# netx90_app register map
File version: 1.0
CPU: CM4 r0p1, little endian, MPU, FPU, 4 interrupt priority bits, 78 interrupts
Registers are 32-bit, read-write, reset 0x0 unless marked. A register's access mark holds for its fields unless they carry their own. Offsets are from the block's base; [hi:lo] are bit positions; 'fields as' and 'values as' point back to an identical list.

## aes
Base 0xFF080300
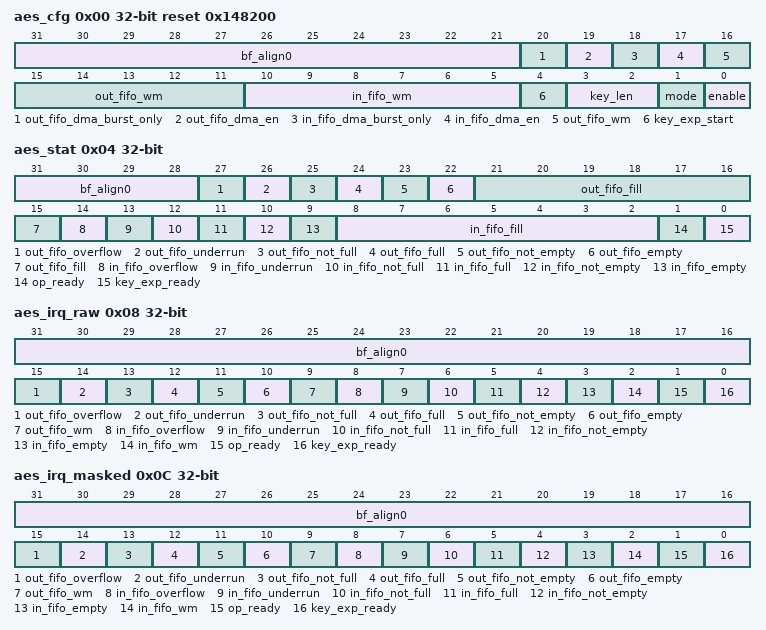
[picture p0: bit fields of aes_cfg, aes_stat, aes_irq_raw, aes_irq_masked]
0x00 aes_cfg reset 0x148200 (reset mask 0x1FFFFF) — AES config register
  [31:21] bf_align0 — bitField alignment value for aeabi compatibility
  [20] out_fifo_dma_burst_only — Generate DMAC burst signal only (output FIFO). When set to '1' the DMAC logic will only generate burst requests to the DMAC. This is not strictly needed for the DMAC implementation, but could result in better system performance.
  [19] out_fifo_dma_en — Enable DMAC control signals for the output FIFO.
  [18] in_fifo_dma_burst_only — Generate DMAC burst signal only (input FIFO). When set to '1' the DMAC logic will only generate burst requests to the DMAC. This is to overcome limitations of the current DMA controller implementation that only accepts burst requests for DMAC controlled memory to peripheral transfers.
  [17] in_fifo_dma_en — Enable DMAC control signals for the input FIFO
  [16:11] out_fifo_wm — Output FIFO watermark level (0..63) used for out_fifo_wm interrupt
  [10:5] in_fifo_wm — Input FIFO watermark level (0..63) used for in_fifo_wm interrupt
  [4] key_exp_start — Start AES key expansion After writing '1', this bit will automatically be reset. Data input can be started when key expansion is ready (see crypt_aes_stat bit 'key_exp_ready').
  [3:2] key_len — AES key length 0: 128 bit 1: 192 bit 2: 256 bit 3: reserved
  [1] mode — AES core operation mode 0: Encrypt 1: Decrypt
  [0] enable — Enables the AES core operation.
0x04 aes_stat ro (reset mask 0xFFFFFFF) — AES status register
  [31:28] bf_align0 — bitField alignment value for aeabi compatibility
  [27] out_fifo_overflow — Output FIFO was overflown, set aes_cfg-enable=0 to reset this bit Note: overflow is only a theoretical FIFO status, because the hardware logic of the AES core won't put data into the FIFO when it's full.
  [26] out_fifo_underrun — Output FIFO was underrun, set aes_cfg-enable=0 to reset this bit
  [25] out_fifo_not_full — Output FIFO is not full
  [24] out_fifo_full — Output FIFO is full
  [23] out_fifo_not_empty — Output FIFO is not empty
  [22] out_fifo_empty — Output FIFO is empty
  [21:15] out_fifo_fill — Fill level of output FIFO in bytes (0..64)
  [14] in_fifo_overflow — Input FIFO was overflown, set aes_cfg-enable=0 to reset this bit
  [13] in_fifo_underrun — Input FIFO was underrun, set aes_cfg-enable=0 to reset this bit Note: underrun is only a theoretical FIFO status, because the hardware logic of the AES core won't fetch data from the FIFO when it's empty.
  [12] in_fifo_not_full — Input FIFO is not full
  [11] in_fifo_full — Input FIFO is full
  [10] in_fifo_not_empty — Input FIFO is not empty
  [9] in_fifo_empty — Input FIFO is empty
  [8:2] in_fifo_fill — Fill level of input FIFO in bytes (0..64)
  [1] op_ready — Set when AES operation ready, i.e. AES core not busy and input FIFO is empty
  [0] key_exp_ready — Set when key expansion procedure is done
0x08 aes_irq_raw (reset mask 0xFFFF) — AES raw IRQ: Read access shows status of unmasked IRQs. IRQs are set automatically and reset by writing to this register: Write access with '1' resets the appropriate IRQ. Write access with '0' does not influence this bit.
  [31:16] bf_align0 — bitField alignment value for aeabi compatibility
  [15] out_fifo_overflow — Output FIFO was overflown, set aes_cfg-enable=0 to reset this bit Note: overflow is only a theoretical FIFO status, because the hardware logic of the AES core won't put data into the FIFO when it's full.
  [14] out_fifo_underrun — Output FIFO was underrun, set aes_cfg-enable=0 to reset this bit
  [13] out_fifo_not_full — Output FIFO is not full
  [12] out_fifo_full — Output FIFO is full
  [11] out_fifo_not_empty — Output FIFO is not empty
  [10] out_fifo_empty — Output FIFO is empty
  [9] out_fifo_wm — Fill level of output FIFO is above watermark (see crypt_aes_cfg bits 'out_fifo_wm')
  [8] in_fifo_overflow — Input FIFO was overflown, set aes_cfg-enable=0 to reset this bit
  [7] in_fifo_underrun — Input FIFO was underrun, set aes_cfg-enable=0 to reset this bit Note: underrun is only a theoretical FIFO status, because the hardware logic of the AES core won't fetch data from the FIFO when it's empty.
  [6] in_fifo_not_full — Input FIFO is not full
  [5] in_fifo_full — Input FIFO is full
  [4] in_fifo_not_empty — Input FIFO is not empty
  [3] in_fifo_empty — Input FIFO is empty
  [2] in_fifo_wm — Fill level of input FIFO is below or equal watermark (see crypt_aes_cfg bits 'in_fifo_wm')
  [1] op_ready — Set when AES operation ready, i.e. AES core not busy and input FIFO is empty
  [0] key_exp_ready — Set when key expansion procedure is done
0x0C aes_irq_masked ro (reset mask 0xFFFF) — AES masked IRQ: Shows status of masked IRQs.
  [31:16] bf_align0 — bitField alignment value for aeabi compatibility
  [15] out_fifo_overflow — Output FIFO was overflown, set aes_cfg-enable=0 to reset this bit
  [14] out_fifo_underrun — Output FIFO was underrun, set aes_cfg-enable=0 to reset this bit
  [13] out_fifo_not_full — Output FIFO is not full
  [12] out_fifo_full — Output FIFO is full
  [11] out_fifo_not_empty — Output FIFO is not empty
  [10] out_fifo_empty — Output FIFO is empty
  [9] out_fifo_wm — Fill level of output FIFO is above watermark (see crypt_aes_cfg bits 'out_fifo_wm')
  [8] in_fifo_overflow — Input FIFO was overflown, set aes_cfg-enable=0 to reset this bit
  [7] in_fifo_underrun — Input FIFO was underrun, set aes_cfg-enable=0 to reset this bit
  [6] in_fifo_not_full — Input FIFO is not full
  [5] in_fifo_full — Input FIFO is full
  [4] in_fifo_not_empty — Input FIFO is not empty
  [3] in_fifo_empty — Input FIFO is empty
  [2] in_fifo_wm — Fill level of input FIFO is below or equal watermark (see crypt_aes_cfg bits 'in_fifo_wm')
  [1] op_ready — Set when AES operation ready, i.e. AES core not busy and input FIFO is empty
  [0] key_exp_ready — Set when key expansion procedure is done
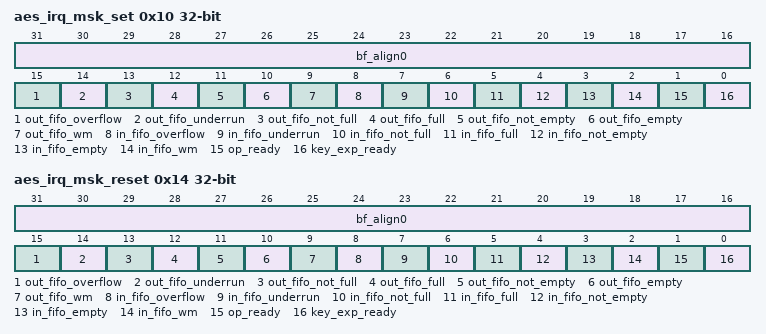
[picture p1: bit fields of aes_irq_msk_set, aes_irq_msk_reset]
0x10 aes_irq_msk_set (reset mask 0xFFFF) — AES IRQ mask set: The IRQ mask enables interrupt requests for corresponding interrupt sources. As its bits might be changed by different software tasks, the IRQ mask register is not writable directly, but by set and reset masks: Write access with '1' sets interrupt mask bit. Write access with '0' does not influence this bit. Read access shows actual interrupt mask. Attention: Before activating interrupt mask, delete old pending interrupts by writing the same value to crypt_aes_irq_raw.
  fields as aes_irq_masked
0x14 aes_irq_msk_reset (reset mask 0xFFFF) — AES IRQ mask reset: This is the corresponding reset mask to disable interrupt requests for corresponding interrupt sources: Write access with '1' resets interrupt mask bit. Write access with '0' does not influence this bit. Read access shows actual interrupt mask.
  fields as aes_irq_masked
0x18 aes_key0 — AES key register 0
  [31:0] val — key bits 31..0
0x1C aes_key1 — AES key register 1
  [31:0] val — key bits 63..32
0x20 aes_key2 — AES key register 2
  [31:0] val — key bits 95..64
0x24 aes_key3 — AES key register 3
  [31:0] val — key bits 127..96
0x28 aes_key4 — AES key register 4
  [31:0] val — key bits 159..128
0x2C aes_key5 — AES key register 5
  [31:0] val — key bits 191..160
0x30 aes_key6 — AES key register 6
  [31:0] val — key bits 223..192
0x34 aes_key7 — AES key register 7
  [31:0] val — key bits 255..224
0x38 aes_din wo — AES FIFO input Unlike all other registers, this address can be written with DWord(32 Bit), Word(16 Bit) or Byte acccss. The FIFO controller will automatically collect data and start AES-calculation, if enough data (4 DWords) are collected.
  [31:0] val — data bits
0x3C aes_dout ro — AES FIFO output
  [31:0] val — data bits
